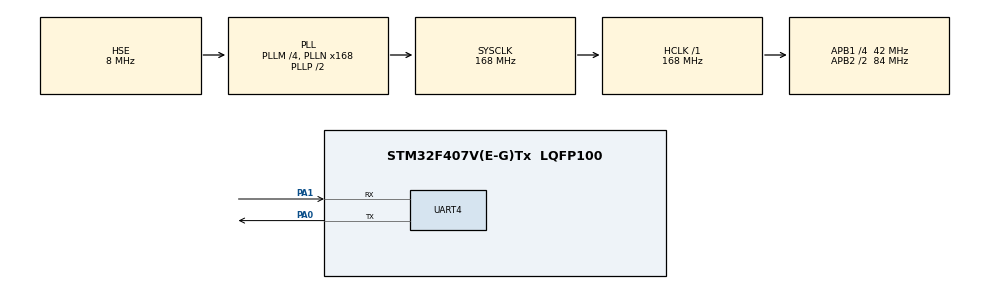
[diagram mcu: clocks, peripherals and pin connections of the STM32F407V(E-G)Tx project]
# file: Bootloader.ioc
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Mcu.Family=STM32F4
Mcu.Name=STM32F407V(E-G)Tx
Mcu.Package=LQFP100
NVIC.PriorityGroup=NVIC_PRIORITYGROUP_4
NVIC.UART4_IRQn=true\:0\:0\:false\:false\:true\:true\:true
PA0-WKUP.Mode=Asynchronous
PA0-WKUP.Signal=UART4_TX
PA1.Mode=Asynchronous
PA1.Signal=UART4_RX
PA13.Mode=Serial_Wire
PA13.Signal=SYS_JTMS-SWDIO
PA14.Mode=Serial_Wire
PA14.Signal=SYS_JTCK-SWCLK
PH0-OSC_IN.Mode=HSE-External-Oscillator
PH0-OSC_IN.Signal=RCC_OSC_IN
PH1-OSC_OUT.Mode=HSE-External-Oscillator
PH1-OSC_OUT.Signal=RCC_OSC_OUT
ProjectManager.HeapSize=0x200
ProjectManager.StackSize=0x400
ProjectManager.TargetToolchain=STM32CubeIDE
RCC.48MHZClocksFreq_Value=84000000
RCC.AHBFreq_Value=168000000
RCC.APB1CLKDivider=RCC_HCLK_DIV4
RCC.APB1Freq_Value=42000000
RCC.APB1TimFreq_Value=84000000
RCC.APB2CLKDivider=RCC_HCLK_DIV2
RCC.APB2Freq_Value=84000000
RCC.APB2TimFreq_Value=168000000
RCC.CortexFreq_Value=168000000
RCC.HCLKFreq_Value=168000000
RCC.HSE_VALUE=8000000
RCC.HSI_VALUE=16000000
RCC.LSE_VALUE=32768
RCC.PLLM=4
RCC.PLLN=168
RCC.PLLSourceVirtual=RCC_PLLSOURCE_HSE
RCC.SYSCLKFreq_VALUE=168000000
RCC.SYSCLKSource=RCC_SYSCLKSOURCE_PLLCLK
RCC.VCOOutputFreq_Value=336000000
UART4.VirtualMode=Asynchronous
board=custom

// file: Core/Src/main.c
/* USER CODE BEGIN Header */
/**
 ******************************************************************************
 * @file           : main.c
 * @brief          : Main program body
 ******************************************************************************
 * @attention
 *
 * <h2><center>&copy; Copyright (c) 2021 STMicroelectronics.
 * All rights reserved.</center></h2>
 *
 * This software component is licensed by ST under BSD 3-Clause license,
 * the "License"; You may not use this file except in compliance with the
 * License. You may obtain a copy of the License at:
 *                        opensource.org/licenses/BSD-3-Clause
 *
 ******************************************************************************
 */
/* USER CODE END Header */
#include "main.h"

/* USER CODE BEGIN Includes */
#define XMODEM_SOH 0x01
#define XMODEM_STX 0x02
#define XMODEM_ETX 0x03
#define XMODEM_EOT 0x04
#define XMODEM_ACK 0x06
#define XMODEM_NAK 0x15
#define XMODEM_CAN 0x18
#define XMODEM_SUB 0x1A

#define XMODEM_DATA_LENGTH 128

#define APPLICATION_START_ADDRESS  0x0800C000 //(FLASH_BASE+ 48*1024)
/* USER CODE BEGIN PTD */
typedef void (*pFunction)( void );
/* USER CODE END PTD */

UART_HandleTypeDef huart4;

void SystemClock_Config(void);
static void MX_GPIO_Init(void);
static void MX_UART4_Init(void);
uint32_t buffer[2000];
typedef enum
{
	IDLE = 0, SOH_RECEIVED, PN1_RECEIVED, PN2_RECEIVED, DATA_RECEIVED,
} XMODEM_RX_STATES;
XMODEM_RX_STATES xModemState = IDLE;
uint8_t checksum;
uint8_t packetNumber;
uint16_t dataIndex;
uint8_t dataBuffer[XMODEM_DATA_LENGTH];
uint32_t bootloaderDelay = 3000;
uint8_t firstFrame = 1;
uint32_t currentProgramAddress;
uint8_t txData[1];
uint8_t rxData[1];

void runApplication();
void EraseApplicationArea( void );
void ProgramAplicationAreaBlock(uint32_t address, uint32_t * data, uint32_t count );
int main(void)
{

	/* MCU Configuration--------------------------------------------------------*/

	/* Reset of all peripherals, Initializes the Flash interface and the Systick. */
	HAL_Init();

	/* Configure the system clock */
	SystemClock_Config();

	/* Initialize all configured peripherals */
	MX_GPIO_Init();
	MX_UART4_Init();
	/* USER CODE BEGIN 2 */
	HAL_UART_Receive_IT(&huart4, rxData, 1);

	HAL_Delay(100);
	txData[0] = XMODEM_NAK;
	HAL_UART_Transmit(&huart4, txData, 1, 100);
	/* USER CODE END 2 */
	uint32_t _t = 0;
	/* Infinite loop */
	while (1)
	{
		if(HAL_GetTick() - _t > 10)
		{
			bootloaderDelay -= 10;
			_t = HAL_GetTick();
		}

		if(bootloaderDelay < 10)
		{
			runApplication();
		}
	}
}

void EraseApplicationArea( void )
{
    //unlock flash
    HAL_FLASH_Unlock();

    FLASH_Erase_Sector( FLASH_SECTOR_3, VOLTAGE_RANGE_3 );
    FLASH_Erase_Sector( FLASH_SECTOR_4, VOLTAGE_RANGE_3 );
    FLASH_Erase_Sector( FLASH_SECTOR_5, VOLTAGE_RANGE_3 );
    FLASH_Erase_Sector( FLASH_SECTOR_6, VOLTAGE_RANGE_3 );
    FLASH_Erase_Sector( FLASH_SECTOR_7, VOLTAGE_RANGE_3 );
    FLASH_Erase_Sector( FLASH_SECTOR_8, VOLTAGE_RANGE_3 );
    FLASH_Erase_Sector( FLASH_SECTOR_9, VOLTAGE_RANGE_3 );
    FLASH_Erase_Sector( FLASH_SECTOR_10, VOLTAGE_RANGE_3 );
    FLASH_Erase_Sector( FLASH_SECTOR_11, VOLTAGE_RANGE_3 );

    //lock flash
    HAL_FLASH_Lock();
}

void runApplication()
{

	pFunction Jump_To_Application = *( (pFunction*) ( APPLICATION_START_ADDRESS + 4 ) );

	__set_CONTROL( 0 );

	SysTick->CTRL = 0; //disable SysTick

	SCB->VTOR = APPLICATION_START_ADDRESS;

	/* Initialize user application's Stack Pointer */
	__set_MSP( *( (uint32_t*) APPLICATION_START_ADDRESS ) );

	Jump_To_Application();
}

void ProgramAplicationAreaBlock(uint32_t address, uint32_t * data, uint32_t count ){
	uint32_t i;

	if(address<APPLICATION_START_ADDRESS) return;

	//unlock flash
	HAL_FLASH_Unlock();

	for(i=0;i<count;i++){
		HAL_FLASH_Program(FLASH_TYPEPROGRAM_WORD, address, *data++);
		address+=sizeof(uint32_t);
	}
	//lock flash
	HAL_FLASH_Lock();
}

void HAL_UART_RxCpltCallback(UART_HandleTypeDef *huart)
{
	/* Prevent unused argument(s) compilation warning */
	HAL_UART_Receive_IT(huart, rxData, 1);
	switch( xModemState )
	{
	case IDLE :
		if( XMODEM_SOH == rxData[0] )
		{
			xModemState = SOH_RECEIVED;
		}
		else if( XMODEM_EOT == rxData[0] )
		{
			//File received
			txData[0] = XMODEM_ACK;
			HAL_UART_Transmit(huart, txData, 1, 100);
			//run application after 100ms
			bootloaderDelay = 100;
		}
		break;
	case SOH_RECEIVED :
		packetNumber = rxData[0];
		xModemState = PN1_RECEIVED;
		break;
	case PN1_RECEIVED :
		if( ( 255 - packetNumber ) == rxData[0] )
		{
			xModemState = PN2_RECEIVED;
			dataIndex = 0;
			checksum = 0;
		}
		else
		{
			//ToDo: send XMODEM_CAN response
		}
		break;
	case PN2_RECEIVED :
		dataBuffer[dataIndex++] = rxData[0];
		checksum += rxData[0];
		if( dataIndex >= XMODEM_DATA_LENGTH )
		{
			xModemState = DATA_RECEIVED;
		}
		break;
	case DATA_RECEIVED :
		if( checksum == rxData[0] )
		{
			//frame received successfully
			if( firstFrame )
			{
				EraseApplicationArea();
				firstFrame = 0;
				currentProgramAddress = APPLICATION_START_ADDRESS;
			}

			//ToDo: write to flash
			ProgramAplicationAreaBlock( currentProgramAddress, (uint32_t *)dataBuffer, sizeof(dataBuffer)/sizeof(uint32_t) );

			currentProgramAddress += sizeof(dataBuffer);

			txData[0] = XMODEM_ACK;
			HAL_UART_Transmit(huart, txData, 1, 100);

			bootloaderDelay = 1000;
		}
		else
		{
			txData[0] = XMODEM_NAK;
			HAL_UART_Transmit(huart, txData, 1, 100);
		}
		xModemState = IDLE;
		break;
	}
	/* NOTE: This function should not be modified, when the callback is needed,
           the HAL_UART_RxCpltCallback could be implemented in the user file
	 */
}

void SystemClock_Config(void)
{
	RCC_OscInitTypeDef RCC_OscInitStruct = {0};
	RCC_ClkInitTypeDef RCC_ClkInitStruct = {0};

	/** Configure the main internal regulator output voltage
	 */
	__HAL_RCC_PWR_CLK_ENABLE();
	__HAL_PWR_VOLTAGESCALING_CONFIG(PWR_REGULATOR_VOLTAGE_SCALE1);
	/** Initializes the RCC Oscillators according to the specified parameters
	 * in the RCC_OscInitTypeDef structure.
	 */
	RCC_OscInitStruct.OscillatorType = RCC_OSCILLATORTYPE_HSE;
	RCC_OscInitStruct.HSEState = RCC_HSE_ON;
	RCC_OscInitStruct.PLL.PLLState = RCC_PLL_ON;
	RCC_OscInitStruct.PLL.PLLSource = RCC_PLLSOURCE_HSE;
	RCC_OscInitStruct.PLL.PLLM = 4;
	RCC_OscInitStruct.PLL.PLLN = 168;
	RCC_OscInitStruct.PLL.PLLP = RCC_PLLP_DIV2;
	RCC_OscInitStruct.PLL.PLLQ = 4;
	if (HAL_RCC_OscConfig(&RCC_OscInitStruct) != HAL_OK)
	{
		Error_Handler();
	}
	/** Initializes the CPU, AHB and APB buses clocks
	 */
	RCC_ClkInitStruct.ClockType = RCC_CLOCKTYPE_HCLK|RCC_CLOCKTYPE_SYSCLK
			|RCC_CLOCKTYPE_PCLK1|RCC_CLOCKTYPE_PCLK2;
	RCC_ClkInitStruct.SYSCLKSource = RCC_SYSCLKSOURCE_PLLCLK;
	RCC_ClkInitStruct.AHBCLKDivider = RCC_SYSCLK_DIV1;
	RCC_ClkInitStruct.APB1CLKDivider = RCC_HCLK_DIV4;
	RCC_ClkInitStruct.APB2CLKDivider = RCC_HCLK_DIV2;

	if (HAL_RCC_ClockConfig(&RCC_ClkInitStruct, FLASH_LATENCY_5) != HAL_OK)
	{
		Error_Handler();
	}
}

static void MX_UART4_Init(void)
{

	huart4.Instance = UART4;
	huart4.Init.BaudRate = 115200;
	huart4.Init.WordLength = UART_WORDLENGTH_8B;
	huart4.Init.StopBits = UART_STOPBITS_1;
	huart4.Init.Parity = UART_PARITY_NONE;
	huart4.Init.Mode = UART_MODE_TX_RX;
	huart4.Init.HwFlowCtl = UART_HWCONTROL_NONE;
	huart4.Init.OverSampling = UART_OVERSAMPLING_16;
	if (HAL_UART_Init(&huart4) != HAL_OK)
	{
		Error_Handler();
	}

}

static void MX_GPIO_Init(void)
{

	/* GPIO Ports Clock Enable */
	__HAL_RCC_GPIOH_CLK_ENABLE();
	__HAL_RCC_GPIOA_CLK_ENABLE();

}

void Error_Handler(void)
{
	__disable_irq();
	while (1)
	{
	}
}

/************************ (C) COPYRIGHT STMicroelectronics *****END OF FILE****/
